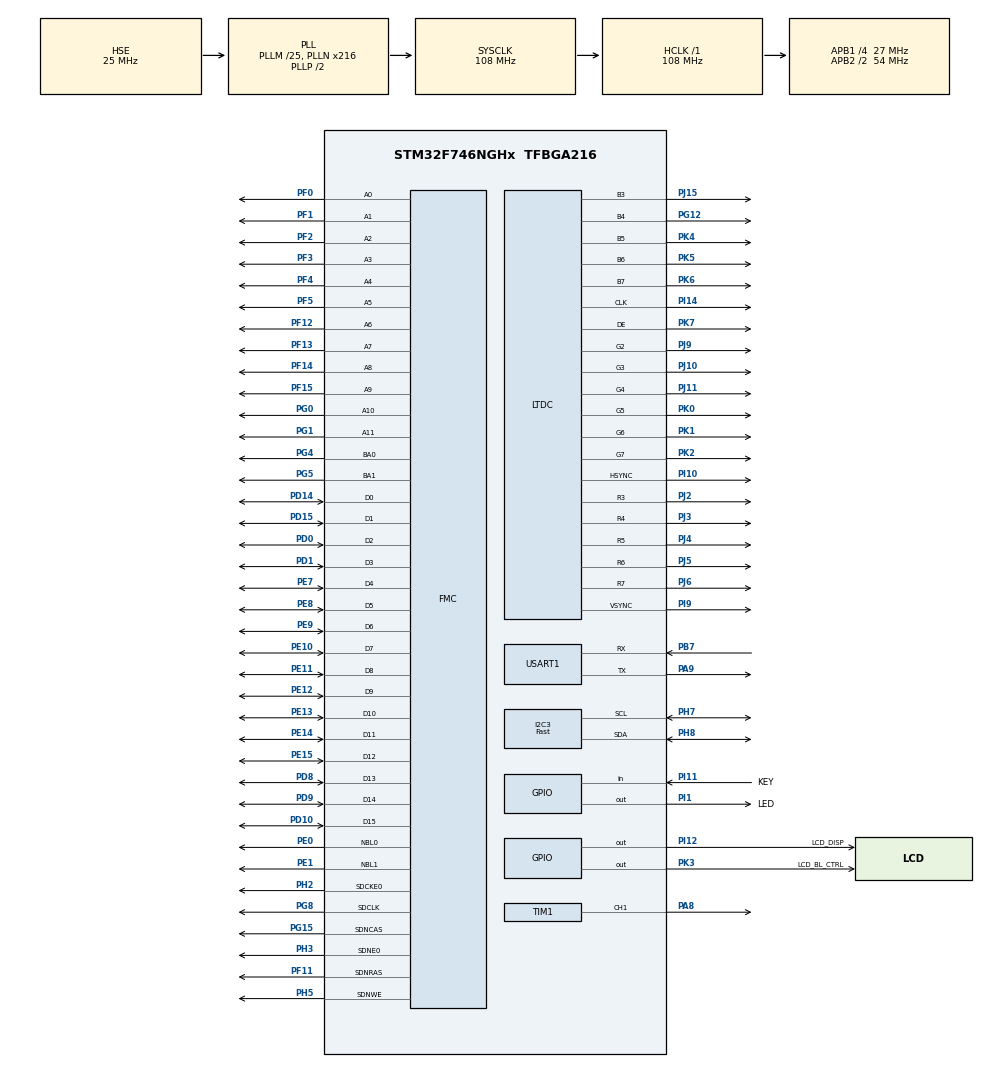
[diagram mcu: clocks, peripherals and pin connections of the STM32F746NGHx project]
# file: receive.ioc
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CORTEX_M7.default_mode_Activation=1
FMC.CASLatency1=FMC_SDRAM_CAS_LATENCY_3
FMC.ExitSelfRefreshDelay1=7
FMC.LoadToActiveDelay1=2
FMC.RCDDelay1=2
FMC.RPDelay1=2
FMC.RPDelay2=2
FMC.ReadBurst1=FMC_SDRAM_RBURST_ENABLE
FMC.ReadBurst2=FMC_SDRAM_RBURST_ENABLE
FMC.RowCycleDelay1=7
FMC.RowCycleDelay2=7
FMC.SDClockPeriod1=FMC_SDRAM_CLOCK_PERIOD_2
FMC.SDClockPeriod2=FMC_SDRAM_CLOCK_PERIOD_2
FMC.SelfRefreshTime1=4
FMC.WriteRecoveryTime1=3
I2C3.I2C_Speed_Mode=I2C_Fast
I2C3.Timing=0x00201625
LTDC.ActiveH=272
LTDC.ActiveW=480
LTDC.Alpha_L0=255
LTDC.FBStartAdress_L0=0xC0000000
LTDC.HBP=13
LTDC.HFP=32
LTDC.HSync=41
LTDC.ImageHeight_L0=272
LTDC.ImageWidth_L0=480
LTDC.Layers=0
LTDC.PixelFormat_L0=LTDC_PIXEL_FORMAT_RGB565
LTDC.VSync=10
LTDC.WindowX1_L0=480
LTDC.WindowY1_L0=272
Mcu.Family=STM32F7
Mcu.Name=STM32F746NGHx
Mcu.Package=TFBGA216
NVIC.DMA2D_IRQn=true\:5\:0\:true\:false\:true\:true\:true\:true
NVIC.LTDC_IRQn=true\:5\:0\:true\:false\:true\:true\:true\:true
NVIC.PriorityGroup=NVIC_PRIORITYGROUP_4
PA8.Signal=S_TIM1_CH1
PA9.Mode=Asynchronous
PA9.Signal=USART1_TX
PB7.Mode=Asynchronous
PB7.Signal=USART1_RX
PD0.Signal=FMC_D2_DA2
PD1.Signal=FMC_D3_DA3
PD10.Signal=FMC_D15_DA15
PD14.Signal=FMC_D0_DA0
PD15.Signal=FMC_D1_DA1
PD8.Signal=FMC_D13_DA13
PD9.Signal=FMC_D14_DA14
PE0.Signal=FMC_NBL0
PE1.Signal=FMC_NBL1
PE10.Signal=FMC_D7_DA7
PE11.Signal=FMC_D8_DA8
PE12.Signal=FMC_D9_DA9
PE13.Signal=FMC_D10_DA10
PE14.Signal=FMC_D11_DA11
PE15.Signal=FMC_D12_DA12
PE7.Signal=FMC_D4_DA4
PE8.Signal=FMC_D5_DA5
PE9.Signal=FMC_D6_DA6
PF0.Signal=FMC_A0
PF1.Signal=FMC_A1
PF11.Signal=FMC_SDNRAS
PF12.Signal=FMC_A6
PF13.Signal=FMC_A7
PF14.Signal=FMC_A8
PF15.Signal=FMC_A9
PF2.Signal=FMC_A2
PF3.Signal=FMC_A3
PF4.Signal=FMC_A4
PF5.Signal=FMC_A5
PG0.Signal=FMC_A10
PG1.Signal=FMC_A11
PG12.Mode=RGB565
PG12.Signal=LTDC_B4
PG15.Signal=FMC_SDNCAS
PG4.Signal=FMC_A14_BA0
PG5.Signal=FMC_A15_BA1
PG8.Signal=FMC_SDCLK
PH0/OSC_IN.Mode=HSE-External-Oscillator
PH0/OSC_IN.Signal=RCC_OSC_IN
PH1/OSC_OUT.Mode=HSE-External-Oscillator
PH1/OSC_OUT.Signal=RCC_OSC_OUT
PH2.Mode=SdramChipSelect1_1
PH2.Signal=FMC_SDCKE0
PH3.Mode=SdramChipSelect1_1
PH3.Signal=FMC_SDNE0
PH5.Signal=FMC_SDNWE
PH7.Mode=I2C
PH7.Signal=I2C3_SCL
PH8.Mode=I2C
PH8.Signal=I2C3_SDA
PI1.GPIO_Label=LED
PI1.GPIO_PuPd=GPIO_NOPULL
PI1.Signal=GPIO_Output
PI1.Stacked=true
PI10.Mode=RGB565
PI10.Signal=LTDC_HSYNC
PI11.GPIO_Label=KEY
PI11.GPIO_PuPd=GPIO_NOPULL
PI11.Signal=GPIO_Input
PI12.GPIO_Label=LCD_DISP
PI12.PinState=GPIO_PIN_SET
PI12.Signal=GPIO_Output
PI14.Mode=RGB565
PI14.Signal=LTDC_CLK
PI9.Mode=RGB565
PI9.Signal=LTDC_VSYNC
PJ10.Mode=RGB565
PJ10.Signal=LTDC_G3
PJ11.Mode=RGB565
PJ11.Signal=LTDC_G4
PJ15.Mode=RGB565
PJ15.Signal=LTDC_B3
PJ2.Mode=RGB565
PJ2.Signal=LTDC_R3
PJ3.Mode=RGB565
PJ3.Signal=LTDC_R4
PJ4.Mode=RGB565
PJ4.Signal=LTDC_R5
PJ5.Mode=RGB565
PJ5.Signal=LTDC_R6
PJ6.Mode=RGB565
PJ6.Signal=LTDC_R7
PJ9.Mode=RGB565
PJ9.Signal=LTDC_G2
PK0.Mode=RGB565
PK0.Signal=LTDC_G5
PK1.Mode=RGB565
PK1.Signal=LTDC_G6
PK2.Mode=RGB565
PK2.Signal=LTDC_G7
PK3.GPIO_Label=LCD_BL_CTRL
PK3.PinState=GPIO_PIN_SET
PK3.Signal=GPIO_Output
PK4.Mode=RGB565
PK4.Signal=LTDC_B5
PK5.Mode=RGB565
PK5.Signal=LTDC_B6
PK6.Mode=RGB565
PK6.Signal=LTDC_B7
PK7.Mode=RGB565
PK7.Signal=LTDC_DE
ProjectManager.HeapSize=0x200
ProjectManager.StackSize=0x400
ProjectManager.TargetToolchain=EWARM V8.32
RCC.AHBFreq_Value=108000000
RCC.APB1CLKDivider=RCC_HCLK_DIV4
RCC.APB1Freq_Value=27000000
RCC.APB1TimFreq_Value=54000000
RCC.APB2CLKDivider=RCC_HCLK_DIV2
RCC.APB2Freq_Value=54000000
RCC.APB2TimFreq_Value=108000000
RCC.CortexFreq_Value=108000000
RCC.HCLKFreq_Value=108000000
RCC.HSE_VALUE=25000000
RCC.HSI_VALUE=16000000
RCC.LSE_VALUE=32768
RCC.PLLM=25
RCC.PLLN=216
RCC.PLLSAIN=384
RCC.PLLSAIR=5
RCC.PLLSAIRDiv=RCC_PLLSAIDIVR_8
RCC.PLLSourceVirtual=RCC_PLLSOURCE_HSE
RCC.SYSCLKFreq_VALUE=108000000
RCC.SYSCLKSource=RCC_SYSCLKSOURCE_PLLCLK
RCC.USBFreq_Value=108000000
RCC.VCOOutputFreq_Value=216000000
SH.FMC_A0.0=FMC_A0,12b-sda1
SH.FMC_A1.0=FMC_A1,12b-sda1
SH.FMC_A10.0=FMC_A10,12b-sda1
SH.FMC_A11.0=FMC_A11,12b-sda1
SH.FMC_A14_BA0.0=FMC_BA0,FourSdramBanks1
SH.FMC_A15_BA1.0=FMC_BA1,FourSdramBanks1
SH.FMC_A2.0=FMC_A2,12b-sda1
SH.FMC_A3.0=FMC_A3,12b-sda1
SH.FMC_A4.0=FMC_A4,12b-sda1
SH.FMC_A5.0=FMC_A5,12b-sda1
SH.FMC_A6.0=FMC_A6,12b-sda1
SH.FMC_A7.0=FMC_A7,12b-sda1
SH.FMC_A8.0=FMC_A8,12b-sda1
SH.FMC_A9.0=FMC_A9,12b-sda1
SH.FMC_D0_DA0.0=FMC_D0,sd-16b-d1
SH.FMC_D10_DA10.0=FMC_D10,sd-16b-d1
SH.FMC_D11_DA11.0=FMC_D11,sd-16b-d1
SH.FMC_D12_DA12.0=FMC_D12,sd-16b-d1
SH.FMC_D13_DA13.0=FMC_D13,sd-16b-d1
SH.FMC_D14_DA14.0=FMC_D14,sd-16b-d1
SH.FMC_D15_DA15.0=FMC_D15,sd-16b-d1
SH.FMC_D1_DA1.0=FMC_D1,sd-16b-d1
SH.FMC_D2_DA2.0=FMC_D2,sd-16b-d1
SH.FMC_D3_DA3.0=FMC_D3,sd-16b-d1
SH.FMC_D4_DA4.0=FMC_D4,sd-16b-d1
SH.FMC_D5_DA5.0=FMC_D5,sd-16b-d1
SH.FMC_D6_DA6.0=FMC_D6,sd-16b-d1
SH.FMC_D7_DA7.0=FMC_D7,sd-16b-d1
SH.FMC_D8_DA8.0=FMC_D8,sd-16b-d1
SH.FMC_D9_DA9.0=FMC_D9,sd-16b-d1
SH.FMC_NBL0.0=FMC_NBL0,Sd2ByteEnable1
SH.FMC_NBL1.0=FMC_NBL1,Sd2ByteEnable1
SH.FMC_SDCLK.0=FMC_SDCLK,12b-sda1
SH.FMC_SDNCAS.0=FMC_SDNCAS,12b-sda1
SH.FMC_SDNRAS.0=FMC_SDNRAS,12b-sda1
SH.FMC_SDNWE.0=FMC_SDNWE,12b-sda1
SH.S_TIM1_CH1.0=TIM1_CH1,PWM Generation1 CH1
STMicroelectronics.X-CUBE-TOUCHGFX.4.27.0.ApplicationCcGraphicsJjApplication=TouchGFXOoGenerator
STMicroelectronics.X-CUBE-TOUCHGFX.4.27.0.tgfx_custom_height=272
STMicroelectronics.X-CUBE-TOUCHGFX.4.27.0.tgfx_display_interface=disp_ltdc
STMicroelectronics.X-CUBE-TOUCHGFX.4.27.0_IsPackSelfContextualization=true
TIM1.Channel-PWM\ Generation1\ CH1=TIM_CHANNEL_1
TIM1.Prescaler=15
USART1.VirtualMode-Asynchronous=VM_ASYNC
VP_CRC_VS_CRC.Mode=CRC_Activate
VP_DMA2D_VS_DMA2D.Mode=DMA2D_Activate
VP_STMicroelectronics.X-CUBE-TOUCHGFX_VS_GraphicsJjApplication_4.27.0.Mode=GraphicsJjApplication
VP_TIM1_VS_ClockSourceINT.Mode=Internal
board=custom

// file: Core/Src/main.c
/* USER CODE BEGIN Header */
/**
  ******************************************************************************
  * @file           : main.c
  * @brief          : Main program body
  ******************************************************************************
  * @attention
  *
  * Copyright (c) 2026 STMicroelectronics.
  * All rights reserved.
  *
  * This software is licensed under terms that can be found in the LICENSE file
  * in the root directory of this software component.
  * If no LICENSE file comes with this software, it is provided AS-IS.
  *
  ******************************************************************************
  */
/* USER CODE END Header */
#include "main.h"
#include "crc.h"
#include "dma2d.h"
#include "i2c.h"
#include "ltdc.h"
#include "tim.h"
#include "usart.h"
#include "gpio.h"
#include "fmc.h"
#include "app_touchgfx.h"

/* USER CODE BEGIN Includes */
#include "lwip.h"
#include "luart.h"
/* USER CODE END Includes */

void SystemClock_Config(void);
static void MPU_Config(void);

int main(void)
{

  /* MPU Configuration--------------------------------------------------------*/
  MPU_Config();

  /* MCU Configuration--------------------------------------------------------*/

  /* Reset of all peripherals, Initializes the Flash interface and the Systick. */
  HAL_Init();

  /* Configure the system clock */
  SystemClock_Config();

  /* Initialize all configured peripherals */
  MX_GPIO_Init();
  MX_TIM1_Init();
  MX_USART1_UART_Init();
  MX_CRC_Init();
  MX_DMA2D_Init();
  MX_FMC_Init();
  MX_LTDC_Init();
  MX_I2C3_Init();
  MX_TouchGFX_Init();
  /* USER CODE BEGIN 2 */
  MX_LWIP_Init();
  MX_LUART_Init();
  /* USER CODE END 2 */

  /* Infinite loop */
  /* USER CODE BEGIN WHILE */
  uint32_t led_last = 0;
  while (1)
  {
    /* USER CODE END WHILE */

    MX_TouchGFX_Process();

    /* USER CODE BEGIN 3 */
    MX_LWIP_Process();
    Luart_Poll();
    Luart_SelfTest(HAL_GetTick());
    /* LED 心跳:0.5Hz 闪烁,指示系统正常运行 */
    if ((HAL_GetTick() - led_last) >= 500u)
    {
      led_last = HAL_GetTick();
      HAL_GPIO_TogglePin(LED_GPIO_Port, LED_Pin);
    }
    /* USER CODE END 3 */
  }
  /* USER CODE END 3 */
}

void SystemClock_Config(void)
{
  RCC_OscInitTypeDef RCC_OscInitStruct = {0};
  RCC_ClkInitTypeDef RCC_ClkInitStruct = {0};

  /** Configure the main internal regulator output voltage
  */
  __HAL_RCC_PWR_CLK_ENABLE();
  __HAL_PWR_VOLTAGESCALING_CONFIG(PWR_REGULATOR_VOLTAGE_SCALE3);

  /** Initializes the RCC Oscillators according to the specified parameters
  * in the RCC_OscInitTypeDef structure.
  */
  RCC_OscInitStruct.OscillatorType = RCC_OSCILLATORTYPE_HSE;
  RCC_OscInitStruct.HSEState = RCC_HSE_ON;
  RCC_OscInitStruct.PLL.PLLState = RCC_PLL_ON;
  RCC_OscInitStruct.PLL.PLLSource = RCC_PLLSOURCE_HSE;
  RCC_OscInitStruct.PLL.PLLM = 25;
  RCC_OscInitStruct.PLL.PLLN = 216;
  RCC_OscInitStruct.PLL.PLLP = RCC_PLLP_DIV2;
  RCC_OscInitStruct.PLL.PLLQ = 2;
  if (HAL_RCC_OscConfig(&RCC_OscInitStruct) != HAL_OK)
  {
    Error_Handler();
  }

  /** Initializes the CPU, AHB and APB buses clocks
  */
  RCC_ClkInitStruct.ClockType = RCC_CLOCKTYPE_HCLK|RCC_CLOCKTYPE_SYSCLK
                              |RCC_CLOCKTYPE_PCLK1|RCC_CLOCKTYPE_PCLK2;
  RCC_ClkInitStruct.SYSCLKSource = RCC_SYSCLKSOURCE_PLLCLK;
  RCC_ClkInitStruct.AHBCLKDivider = RCC_SYSCLK_DIV1;
  RCC_ClkInitStruct.APB1CLKDivider = RCC_HCLK_DIV4;
  RCC_ClkInitStruct.APB2CLKDivider = RCC_HCLK_DIV2;

  if (HAL_RCC_ClockConfig(&RCC_ClkInitStruct, FLASH_LATENCY_3) != HAL_OK)
  {
    Error_Handler();
  }
}

 /* MPU Configuration */

void MPU_Config(void)
{
  MPU_Region_InitTypeDef MPU_InitStruct = {0};

  HAL_MPU_Disable();

  /* Region 0: SDRAM frame buffer 0xC0000000, 64MB, read/write, non-cacheable, non-bufferable */
  MPU_InitStruct.Enable           = MPU_REGION_ENABLE;
  MPU_InitStruct.Number           = MPU_REGION_NUMBER0;
  MPU_InitStruct.BaseAddress      = 0xC0000000;
  MPU_InitStruct.Size             = MPU_REGION_SIZE_64MB;
  MPU_InitStruct.SubRegionDisable = 0x00;
  MPU_InitStruct.TypeExtField     = MPU_TEX_LEVEL0;
  MPU_InitStruct.AccessPermission = MPU_REGION_FULL_ACCESS;
  MPU_InitStruct.DisableExec      = MPU_INSTRUCTION_ACCESS_DISABLE;
  MPU_InitStruct.IsShareable      = MPU_ACCESS_NOT_SHAREABLE;
  MPU_InitStruct.IsCacheable      = MPU_ACCESS_NOT_CACHEABLE;
  MPU_InitStruct.IsBufferable     = MPU_ACCESS_NOT_BUFFERABLE;

  HAL_MPU_ConfigRegion(&MPU_InitStruct);

  HAL_MPU_Enable(MPU_PRIVILEGED_DEFAULT);
}

void Error_Handler(void)
{
  __disable_irq();
  while (1)
  {
  }
}
